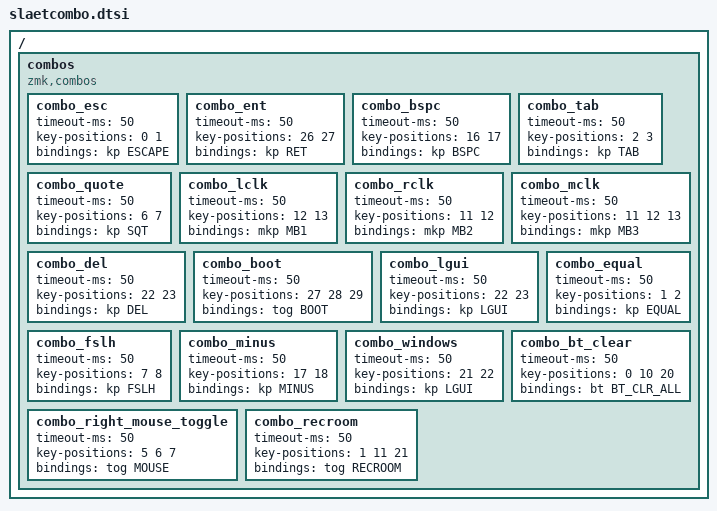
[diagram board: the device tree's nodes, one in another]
#include <behaviors.dtsi>

#include <behaviors/rgbled_widget.dtsi>

#include <dt-bindings/zmk/keys.h>
#include <dt-bindings/zmk/mouse.h>
#include <dt-bindings/zmk/bt.h>
#include <dt-bindings/zmk/outputs.h>
#include <dt-bindings/zmk/pointing.h>

#define DEFAULT     0
#define NUMLAYER    1
#define NAVLAYER    2
#define MOUSE       3
#define FUNCTION    4
#define BOOT        5
#define RECROOM     6

/{
    combos {
        compatible = "zmk,combos";
        combo_esc {
            timeout-ms = <50>;
            key-positions = <0 1>;
            bindings = <&kp ESCAPE>;
        };
        combo_ent {
            timeout-ms = <50>;
            key-positions = <26 27>;
            bindings = <&kp RET>;
        };
        combo_bspc {
            timeout-ms = <50>;
            key-positions = <16 17>;
            bindings = <&kp BSPC>;
        };
        combo_tab {
            timeout-ms = <50>;
            key-positions = <2 3>;
            bindings = <&kp TAB>;
        };
        combo_quote {
            timeout-ms = <50>;
            key-positions = <6 7>;
            bindings = <&kp SQT>;
        };
        combo_lclk {
            timeout-ms = <50>;
            key-positions = <12 13>;
            bindings = <&mkp MB1>;
        };
        combo_rclk {
            timeout-ms = <50>;
            key-positions = <11 12>;
            bindings = <&mkp MB2>;
        };
        combo_mclk {
            timeout-ms = <50>;
            key-positions = <11 12 13>;
            bindings = <&mkp MB3>;
        };
        combo_del {
            timeout-ms = <50>;
            key-positions = <22 23>;
            bindings = <&kp DEL>;
        };
        combo_boot {
            timeout-ms = <50>;
            key-positions = <27 28 29>;
            bindings = <&tog BOOT>;
        };
        combo_lgui {
            timeout-ms = <50>;
            key-positions = <22 23>;
            bindings = <&kp LGUI>;
        };
        combo_equal {
            timeout-ms = <50>;
            key-positions = <1 2>;
            bindings = <&kp EQUAL>;
        };
        combo_fslh {
            timeout-ms = <50>;
            key-positions = <7 8>;
            bindings = <&kp FSLH>;
        };
        combo_minus {
            timeout-ms = <50>;
            key-positions = <17 18>;
            bindings = <&kp MINUS>;
        };
        combo_windows {
            timeout-ms = <50>;
            key-positions = <21 22>;
            bindings = <&kp LGUI>;
        };           
        combo_right_mouse_toggle {
            timeout-ms = <50>;
            key-positions = <5 6 7>;
            bindings = <&tog MOUSE>;
        };
        combo_bt_clear {
            timeout-ms = <50>;
            key-positions = <0 10 20>;
            bindings = <&bt BT_CLR_ALL>;
        };
        combo_recroom {
            timeout-ms = <50>;
            key-positions = <1 11 21>;
            bindings = <&tog RECROOM>; 
        };
    };
};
